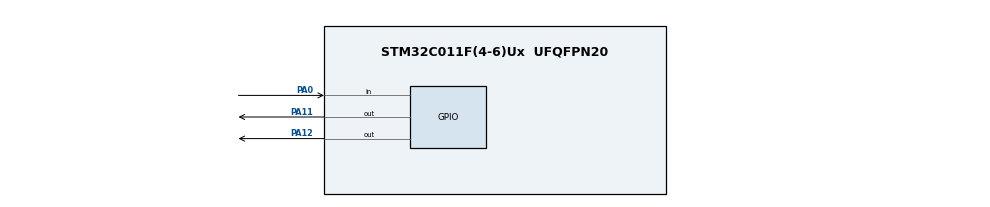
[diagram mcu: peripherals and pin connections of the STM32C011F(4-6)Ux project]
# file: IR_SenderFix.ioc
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Mcu.Family=STM32C0
Mcu.Name=STM32C011F(4-6)Ux
Mcu.Package=UFQFPN20
NVIC.TIM16_IRQn=true\:0\:0\:false\:false\:true\:true\:true\:true
PA0.GPIO_PuPd=GPIO_PULLUP
PA0.Signal=GPIO_Input
PA11\ [PA9].GPIO_ModeDefaultOutputPP=GPIO_MODE_OUTPUT_OD
PA11\ [PA9].GPIO_PuPd=GPIO_NOPULL
PA11\ [PA9].Signal=GPIO_Output
PA12\ [PA10].GPIO_ModeDefaultOutputPP=GPIO_MODE_OUTPUT_OD
PA12\ [PA10].GPIO_PuPd=GPIO_NOPULL
PA12\ [PA10].Signal=GPIO_Output
ProjectManager.HeapSize=0x200
ProjectManager.StackSize=0x400
ProjectManager.TargetToolchain=STM32CubeIDE
RCC.ADCFreq_Value=24000000
RCC.AHBFreq_Value=24000000
RCC.CortexFreq_Value=24000000
RCC.EXTERNAL_CLOCK_VALUE=12288000
RCC.HCLKFreq_Value=24000000
RCC.HSE_VALUE=8000000
RCC.HSISYSCLKDivider=RCC_HSI_DIV2
RCC.HSI_VALUE=48000000
RCC.LSE_VALUE=32768
RCC.SYSCLKFreq_VALUE=24000000
VP_TIM16_VS_ClockSourceINT.Mode=Enable_Timer
board=custom

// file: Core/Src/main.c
/* USER CODE BEGIN Header */
/**
  ******************************************************************************
  * @file           : main.c
  * @brief          : Main program body
  ******************************************************************************
  * @attention
  *
  * Copyright (c) 2025 STMicroelectronics.
  * All rights reserved.
  *
  * This software is licensed under terms that can be found in the LICENSE file
  * in the root directory of this software component.
  * If no LICENSE file comes with this software, it is provided AS-IS.
  *
  ******************************************************************************
  */
/* USER CODE END Header */
#include "main.h"

/* USER CODE BEGIN Includes */
#include "stdlib.h"
#include "stdio.h"
/* USER CODE END Includes */

TIM_HandleTypeDef htim16;

void SystemClock_Config(void);
static void MX_GPIO_Init(void);
static void MX_TIM16_Init(void);

/* USER CODE BEGIN 0 */
typedef struct
{
	uint8_t m_Start;		// set to 1 to start meassurement
	uint8_t m_Run;			// 1, if meassurement is running
	uint32_t m_TimeStart;	// start time
	uint32_t m_TimeEnd;		// end time
	uint32_t m_Cnt;
	uint8_t m_low;
} MESS;

MESS g_Data = {0};
/* USER CODE END 0 */

int main(void)
{

  /* MCU Configuration--------------------------------------------------------*/

  /* Reset of all peripherals, Initializes the Flash interface and the Systick. */
  HAL_Init();

  /* Configure the system clock */
  SystemClock_Config();

  /* Initialize all configured peripherals */
  MX_GPIO_Init();
  MX_TIM16_Init();
  /* USER CODE BEGIN 2 */
  HAL_TIM_Base_Start_IT(&htim16);
  /* USER CODE END 2 */

  /* Infinite loop */
  while (1)
  {
    int diff = 0;
	g_Data.m_Start=1;	// start
	HAL_Delay(400);		// wait 400 ms

	//HAL_GPIO_TogglePin(GPIOA, GPIO_PIN_12);
	diff = g_Data.m_TimeEnd - g_Data.m_TimeStart;	// calculate end - start to see in debugger. breakpoint next line
	if(diff > 400)
	{
		//HAL_GPIO_TogglePin(GPIOA, GPIO_PIN_12);
		HAL_GPIO_WritePin(GPIOA, GPIO_PIN_12, GPIO_PIN_SET);
	}
	if(diff < 390)
		{
			//HAL_GPIO_TogglePin(GPIOA, GPIO_PIN_12);
			HAL_GPIO_WritePin(GPIOA, GPIO_PIN_12, GPIO_PIN_RESET);
		}

	//printf("test %d\n\r",diff);
  }
}

void SystemClock_Config(void)
{
  RCC_OscInitTypeDef RCC_OscInitStruct = {0};
  RCC_ClkInitTypeDef RCC_ClkInitStruct = {0};

  __HAL_FLASH_SET_LATENCY(FLASH_LATENCY_0);

  /** Initializes the RCC Oscillators according to the specified parameters
  * in the RCC_OscInitTypeDef structure.
  */
  RCC_OscInitStruct.OscillatorType = RCC_OSCILLATORTYPE_HSI;
  RCC_OscInitStruct.HSIState = RCC_HSI_ON;
  RCC_OscInitStruct.HSIDiv = RCC_HSI_DIV2;
  RCC_OscInitStruct.HSICalibrationValue = RCC_HSICALIBRATION_DEFAULT;
  if (HAL_RCC_OscConfig(&RCC_OscInitStruct) != HAL_OK)
  {
    Error_Handler();
  }

  /** Initializes the CPU, AHB and APB buses clocks
  */
  RCC_ClkInitStruct.ClockType = RCC_CLOCKTYPE_HCLK|RCC_CLOCKTYPE_SYSCLK
                              |RCC_CLOCKTYPE_PCLK1;
  RCC_ClkInitStruct.SYSCLKSource = RCC_SYSCLKSOURCE_HSI;
  RCC_ClkInitStruct.SYSCLKDivider = RCC_SYSCLK_DIV1;
  RCC_ClkInitStruct.AHBCLKDivider = RCC_HCLK_DIV1;
  RCC_ClkInitStruct.APB1CLKDivider = RCC_APB1_DIV1;

  if (HAL_RCC_ClockConfig(&RCC_ClkInitStruct, FLASH_LATENCY_0) != HAL_OK)
  {
    Error_Handler();
  }
}

static void MX_TIM16_Init(void)
{

  htim16.Instance = TIM16;
  htim16.Init.Prescaler = 0;
  htim16.Init.CounterMode = TIM_COUNTERMODE_UP;
  htim16.Init.Period = 315;			// 38 kHz
  htim16.Init.ClockDivision = TIM_CLOCKDIVISION_DIV1;
  htim16.Init.RepetitionCounter = 0;
  htim16.Init.AutoReloadPreload = TIM_AUTORELOAD_PRELOAD_ENABLE;
  if (HAL_TIM_Base_Init(&htim16) != HAL_OK)
  {
    Error_Handler();
  }

}

static void MX_GPIO_Init(void)
{
  GPIO_InitTypeDef GPIO_InitStruct = {0};

  /* GPIO Ports Clock Enable */
  __HAL_RCC_GPIOA_CLK_ENABLE();

  /*Configure GPIO pin Output Level */
  HAL_GPIO_WritePin(GPIOA, GPIO_PIN_11|GPIO_PIN_12, GPIO_PIN_RESET);

  /*Configure GPIO pin : PA0  */
  GPIO_InitStruct.Pin = GPIO_PIN_0;
  GPIO_InitStruct.Mode = GPIO_MODE_INPUT;  //GPIO_MODE_INPUT;
  GPIO_InitStruct.Pull = GPIO_NOPULL;
  HAL_GPIO_Init(GPIOA, &GPIO_InitStruct);

  /*Configure GPIO pins : PA11 PA12 */
  GPIO_InitStruct.Pin = GPIO_PIN_11|GPIO_PIN_12;
  GPIO_InitStruct.Mode = GPIO_MODE_OUTPUT_PP;
  GPIO_InitStruct.Pull = GPIO_NOPULL;
  GPIO_InitStruct.Speed = GPIO_SPEED_FREQ_LOW;
  HAL_GPIO_Init(GPIOA, &GPIO_InitStruct);

}

/* USER CODE BEGIN 4 */
// 38 kHz -> 26,3us
void HAL_TIM_PeriodElapsedCallback (TIM_HandleTypeDef * htim)
{
	if(g_Data.m_Run)
	{
		g_Data.m_Cnt++;
		HAL_GPIO_TogglePin(GPIOA, GPIO_PIN_11);
		if(!HAL_GPIO_ReadPin(GPIOA, GPIO_PIN_0))		// wait for low
		{
			g_Data.m_low = 1;
			g_Data.m_TimeEnd = 0;						// start timer
		}
		if(g_Data.m_low && HAL_GPIO_ReadPin(GPIOA, GPIO_PIN_0))	// next high is ready
		{
			//g_Data.m_Run = 0;
			g_Data.m_TimeEnd++;							// count time
			;
		}
		//if (g_Data.m_Cnt >= (120000/15))		// 120 ms stop timer
		if (g_Data.m_Cnt >= (100000/15))		// 120 ms stop timer
		{
			g_Data.m_Run = 0;
		}
		if(!g_Data.m_Run)
		{
			HAL_GPIO_WritePin(GPIOA, GPIO_PIN_11, 1);	// switch off
		}
	}
	if(g_Data.m_Start == 1)
	{
		g_Data.m_Run = 1;
		g_Data.m_TimeStart = 0;	// HAL_GetTick();

		g_Data.m_Start = 0;
		g_Data.m_Cnt = 0;
		g_Data.m_low = 0;
	}
}
/* USER CODE END 4 */

void Error_Handler(void)
{
  __disable_irq();
  while (1)
  {
  }
}
